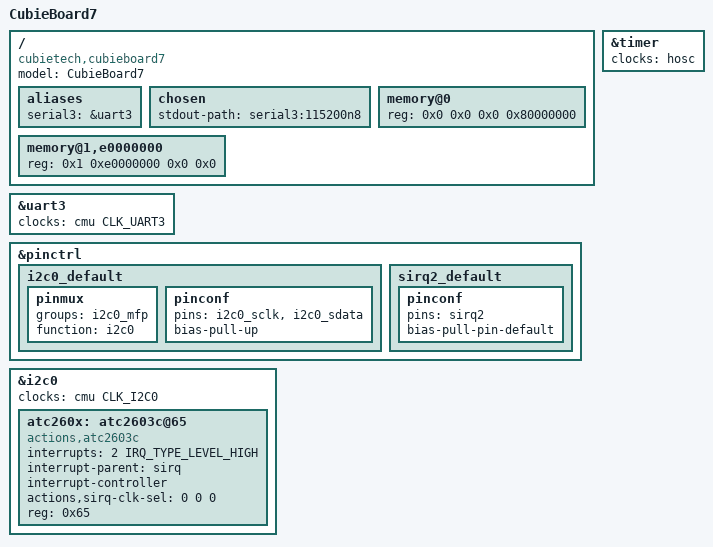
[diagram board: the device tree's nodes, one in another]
// SPDX-License-Identifier: (GPL-2.0+ OR MIT)
/*
 * Copyright (c) 2017 Andreas Färber
 */

/dts-v1/;

#include "s700.dtsi"

/ {
	compatible = "cubietech,cubieboard7", "actions,s700";
	model = "CubieBoard7";

	aliases {
		serial3 = &uart3;
	};

	chosen {
		stdout-path = "serial3:115200n8";
	};

	memory@0 {
		device_type = "memory";
		reg = <0x0 0x0 0x0 0x80000000>;
	};

	memory@1,e0000000 {
		device_type = "memory";
		reg = <0x1 0xe0000000 0x0 0x0>;
	};
};

&timer {
	clocks = <&hosc>;
};

&uart3 {
	status = "okay";
	clocks = <&cmu CLK_UART3>;
};

&pinctrl {
        i2c0_default: i2c0_default {
                pinmux {
                        groups = "i2c0_mfp";
                        function = "i2c0";
                };
                pinconf {
                        pins = "i2c0_sclk", "i2c0_sdata";
                        bias-pull-up;
                };
        };

	sirq2_default: sirq2_default {
/*
                pinmux {
                        groups = "sirq2_dummy";
                        function = "sirq2";
                };
*/
		pinconf {
			pins = "sirq2";
                        bias-pull-pin-default;
//                        bias-pull-up;
		};
	};
};

&i2c0 {
        status = "okay";
	clocks = <&cmu CLK_I2C0>;
        atc260x: atc2603c@65 {
                compatible = "actions,atc2603c";
		interrupts = <2 IRQ_TYPE_LEVEL_HIGH>;
		interrupt-parent = <&sirq>;
		interrupt-controller;
		#interrupt-cells = <1>;
		actions,sirq-clk-sel = <0 0 0>;
                reg = <0x65>;
        };
};
